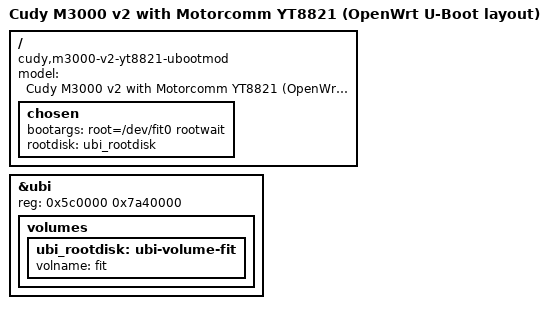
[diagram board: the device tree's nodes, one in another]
// SPDX-License-Identifier: (GPL-2.0 OR MIT)

/dts-v1/;
#include "mt7981b-cudy-m3000-v2-yt8821.dtsi"

/ {
	model = "Cudy M3000 v2 with Motorcomm YT8821 (OpenWrt U-Boot layout)";
	compatible = "cudy,m3000-v2-yt8821-ubootmod", "mediatek,mt7981";

	chosen {
		bootargs = "root=/dev/fit0 rootwait";
		rootdisk = <&ubi_rootdisk>;
	};
};

&ubi {
	reg = <0x5c0000 0x7a40000>;

	volumes {
		ubi_rootdisk: ubi-volume-fit {
			volname = "fit";
		};
	};
};
